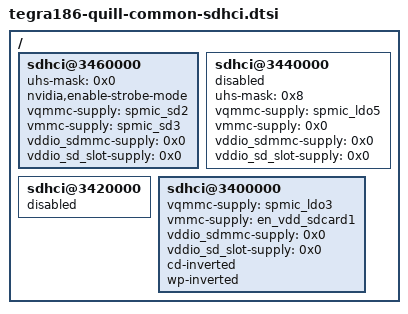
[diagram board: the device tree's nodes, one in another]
/*
 * Copyright (c) 2015-2016, NVIDIA CORPORATION.  All rights reserved.
 *
 * This program is free software; you can redistribute it and/or modify
 * it under the terms of the GNU General Public License as published by
 * the Free Software Foundation; either version 2 of the License, or
 * (at your option) any later version.
 *
 * This program is distributed in the hope that it will be useful, but WITHOUT
 * ANY WARRANTY; without even the implied warranty of MERCHANTABILITY or
 * FITNESS FOR A PARTICULAR PURPOSE.  See the GNU General Public License for
 * more details.
 *
 * You should have received a copy of the GNU General Public License along
 * with this program; if not, write to the Free Software Foundation, Inc.,
 * 51 Franklin Street, Fifth Floor, Boston, MA  02110-1301, USA.
 */

/ {
	sdhci@3460000 {
		uhs-mask = <0x0>; /*enable HS400 mode*/
		nvidia,enable-strobe-mode;
		vqmmc-supply = <&spmic_sd2>;
		vmmc-supply = <&spmic_sd3>;
		vddio_sdmmc-supply = <0x0>;
		vddio_sd_slot-supply = <0x0>;
		status = "okay";
	};

	sdhci@3440000 {
		uhs-mask = <0x8>;
		vqmmc-supply = <&spmic_ldo5>;
		vmmc-supply = <0x0>;
		vddio_sdmmc-supply = <0x0>;
		vddio_sd_slot-supply = <0x0>;
		status = "disabled";
	};

	sdhci@3420000 {
		status = "disabled";
	};

	sdhci@3400000 {
		vqmmc-supply = <&spmic_ldo3>;
		vmmc-supply = <&en_vdd_sdcard1>;
		vddio_sdmmc-supply = <0x0>;
		vddio_sd_slot-supply = <0x0>;
		cd-inverted;
		wp-inverted;
		status = "okay";
	};
};
